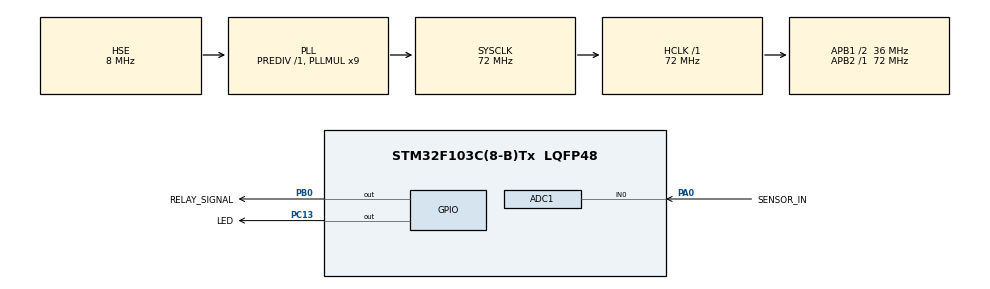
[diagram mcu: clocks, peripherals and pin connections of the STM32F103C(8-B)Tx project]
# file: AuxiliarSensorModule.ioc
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ADC1.Channel-3\#ChannelRegularConversion=ADC_CHANNEL_0
ADC1.ContinuousConvMode=DISABLE
ADC1.NbrOfConversionFlag=1
ADC1.Rank-3\#ChannelRegularConversion=1
ADC1.SamplingTime-3\#ChannelRegularConversion=ADC_SAMPLETIME_1CYCLE_5
ADC1.master=1
Dma.ADC1.0.Direction=DMA_PERIPH_TO_MEMORY
Dma.ADC1.0.Instance=DMA1_Channel1
Dma.ADC1.0.MemDataAlignment=DMA_MDATAALIGN_HALFWORD
Dma.ADC1.0.MemInc=DMA_MINC_ENABLE
Dma.ADC1.0.Mode=DMA_NORMAL
Dma.ADC1.0.PeriphDataAlignment=DMA_PDATAALIGN_HALFWORD
Dma.ADC1.0.PeriphInc=DMA_PINC_DISABLE
Dma.ADC1.0.Priority=DMA_PRIORITY_LOW
Dma.Request0=ADC1
Mcu.Family=STM32F1
Mcu.Name=STM32F103C(8-B)Tx
Mcu.Package=LQFP48
NVIC.ADC1_2_IRQn=true\:0\:0\:false\:false\:true\:true\:true\:true
NVIC.DMA1_Channel1_IRQn=true\:0\:0\:false\:false\:true\:false\:true\:true
NVIC.PriorityGroup=NVIC_PRIORITYGROUP_4
PA0-WKUP.GPIO_Label=SENSOR_IN
PA0-WKUP.Signal=ADCx_IN0
PA13.Mode=Serial_Wire
PA13.Signal=SYS_JTMS-SWDIO
PA14.Mode=Serial_Wire
PA14.Signal=SYS_JTCK-SWCLK
PB0.GPIO_Label=RELAY_SIGNAL
PB0.Signal=GPIO_Output
PC13-TAMPER-RTC.GPIO_Label=LED
PC13-TAMPER-RTC.Signal=GPIO_Output
PD0-OSC_IN.Mode=HSE-External-Oscillator
PD0-OSC_IN.Signal=RCC_OSC_IN
PD1-OSC_OUT.Mode=HSE-External-Oscillator
PD1-OSC_OUT.Signal=RCC_OSC_OUT
ProjectManager.HeapSize=0x200
ProjectManager.StackSize=0x400
ProjectManager.TargetToolchain=STM32CubeIDE
RCC.ADCPresc=RCC_ADCPCLK2_DIV6
RCC.AHBFreq_Value=72000000
RCC.APB1CLKDivider=RCC_HCLK_DIV2
RCC.APB1Freq_Value=36000000
RCC.APB1TimFreq_Value=72000000
RCC.APB2Freq_Value=72000000
RCC.APB2TimFreq_Value=72000000
RCC.HCLKFreq_Value=72000000
RCC.PLLMUL=RCC_PLL_MUL9
RCC.PLLSourceVirtual=RCC_PLLSOURCE_HSE
RCC.SYSCLKFreq_VALUE=72000000
RCC.SYSCLKSource=RCC_SYSCLKSOURCE_PLLCLK
RCC.USBFreq_Value=72000000
SH.ADCx_IN0.0=ADC1_IN0,IN0
board=custom

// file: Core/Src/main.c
/* USER CODE BEGIN Header */
/**
  ******************************************************************************
  * @file           : main.c
  * @brief          : Main program body
  ******************************************************************************
  * @attention
  *
  * Copyright (c) 2024 STMicroelectronics.
  * All rights reserved.
  *
  * This software is licensed under terms that can be found in the LICENSE file
  * in the root directory of this software component.
  * If no LICENSE file comes with this software, it is provided AS-IS.
  *
  ******************************************************************************
  */
/* USER CODE END Header */
#include "main.h"
#include "adc.h"
#include "dma.h"
#include "gpio.h"

/* USER CODE BEGIN Includes */
#include "stdio.h"
#include "stdbool.h"
#include "string.h"

/* USER CODE END Includes */

/* USER CODE BEGIN PD */
#define ANALOG_READS 1
#define VALUE_STAGE_1 1700 // 70 - 1.51V
#define VALUE_STAGE_2 500 // 110 - 0.64V
#define HISTERESYS 600 //
#define BUFFER_SIZE 10
/* USER CODE END PD */

/* USER CODE BEGIN PV */

/*  ADC  */
uint32_t ADCReadings[ANALOG_READS];
uint32_t anBuff[BUFFER_SIZE] = {0};
bool ADC_Complete = false;
uint32_t mediaRead = 0;
uint8_t buf_cnt = 0;

/*  TIMER  */
uint16_t timer_diff;
uint16_t timer_diff2;
uint16_t timer_diff3;

uint16_t timer_bfr = 0;
uint16_t timer_bfr2 = 0;
uint16_t timer_bfr3 = 0;

int point = 0;

uint16_t timer_curr = 0;
bool relay_status = true;

uint8_t read_cont = 0;

/* USER CODE END PV */

void SystemClock_Config(void);
/* USER CODE BEGIN PFP */

void HAL_ADC_ConvCpltCallback(ADC_HandleTypeDef* hadc);

/* USER CODE END PFP */

int main(void)
{

  /* MCU Configuration--------------------------------------------------------*/

  /* Reset of all peripherals, Initializes the Flash interface and the Systick. */
  HAL_Init();

  /* Configure the system clock */
  SystemClock_Config();

  /* Initialize all configured peripherals */
  MX_GPIO_Init();
  MX_DMA_Init();
  MX_ADC1_Init();
  /* USER CODE BEGIN 2 */

  /*
   * OBS: Uma breve inicialização com LED piscando para verificar que o controlador foi inicializado.
   * */
  for(int i = 0; i < 5; i++) {
	  HAL_GPIO_TogglePin(LED_GPIO_Port,LED_Pin);
	  HAL_Delay(200);
  }
  HAL_GPIO_WritePin(RELAY_SIGNAL_GPIO_Port, RELAY_SIGNAL_Pin, GPIO_PIN_SET);
  HAL_ADC_Start_DMA(&hadc1, (uint32_t*)&ADCReadings, ANALOG_READS);

  /* USER CODE END 2 */

  /* Infinite loop */
  /* USER CODE BEGIN WHILE */
  while (1)
  {
	  timer_curr = HAL_GetTick(); // OBS: Essa função retorna o valor em millissegundos.

	  HAL_GPIO_TogglePin(LED_GPIO_Port,LED_Pin);
	  // HAL_Delay(300); // OBS: Esse delay dentro do loop tá travando o seu código por 300ms a cada interação. Isso não se faz!

	  timer_diff = timer_curr - timer_bfr; // OBS: Show! Você inicializou tudo com 0 e como variáveis globais, então vai funcionar.

	  if (timer_diff >= 100) { // OBS: Você executa esse trecho de código a cada aproximadamento 100ms. OK!
		  HAL_ADC_Start_DMA(&hadc1, (uint32_t*)&ADCReadings, ANALOG_READS); // OBS: Habilita a amostragem do valor das analógicas utilizando DMA. OK!

		  if (ADC_Complete) {	// OBS: Aguarda até as analógicas serem completamente amostradas e convertidas pelo ADC. OK!
			  ADC_Complete = false; // OBS: Atualiza a variável de comunicação do loop com a interrupção. OK!
			  HAL_ADC_Stop_DMA(&hadc1);

			// OBS: Só posiciona o valor lido na analógica na posição da leitura mais antiga, e fica rodando essa variável 'buf_cnt'
			// OBS: Não interessa a posição do valor, no final das contas você vai somar tudo e dividir mesmo.
			anBuff[buf_cnt] = ADCReadings[0];
			buf_cnt++;
			if(buf_cnt == BUFFER_SIZE) {buf_cnt = 0;}

			// OBS: Adicionei a média aqui pois ela somente se altera quando se lê uma nova analógica, logo não faz sentido rodar ela em outro trecho do código
		    // Calcula a média dos valores em anBuff
		    uint32_t sum = 0;

		    for (int i = 0; i < BUFFER_SIZE; i++) {
		      sum += anBuff[i];
		    }
		    mediaRead = sum / BUFFER_SIZE;

      }
      // HAL_ADC_Start_DMA(&hadc1, (uint32_t*)&ADCReadings, ANALOG_READS); // OBS: Você já está habilitando a amostragem do valor das analógicas lá no inicio a cada 100ms.
      	  	  	  	  	  	  	  	  	  	  	  	  	  	  	  	  	   // OBS: Habilitando essa amostragem aqui você tá pedindo para o controlador inicializar a leitura e somente irá ler esse valor 100ms depois.
      	  	  	  	  	  	  	  	  	  	  	  	  	  	  	  	  	   // OBS: Quando você entrar no trecho que roda a cada 100ms o ADC_Complete já vai estar True e com o valor de 100ms atrás.
      timer_bfr = timer_curr; // OBS: Atualiza o novo valor de timer_bfr somente após completar o código completo que roda em 100ms (Amostragem e Leitura da analógica). OK!
    }

	timer_diff2 = timer_curr - timer_bfr2; // OBS: Pelo que entendi você vai usar outro conjunto de variáveis para controlar o tempo da outra função. Então vai precisar desse mesmo processo.
	timer_diff3 = timer_curr - timer_bfr3;
	// OBS: Daria para fazer usando a mesma variável, mas não importa muito para esse rpograma específico. Podemos fazer assim, sem problemas.

	if (timer_diff2 >= 10000) { // Esse trecho executa a cada 1 segundo. Coloquei 1 segundo e troquei a média movel para 10 valores. BUFFER_SIZE = 10;

		if (relay_status){
			// OBS: Observa como funciona a histerese. Depois que o relé liga quando a temperatura passa do VALUE_STAGE_1, ele só desliga depois que desce pelo menos a histerese dese alvo, senão não faz nada e permanece ligado.
			if (mediaRead > VALUE_STAGE_1 ){
				point = 1;
				relay_status = true; // OBS: Considerei o true como sendo a ventoinha ligada (relé desligado pois estamos usando NC do relé). VERIFICAR A LÓGICA!

			}
			if (mediaRead <= VALUE_STAGE_1 ){
				relay_status = false;
				point = 2;
			}

		} else {
			if(!relay_status){
				if(mediaRead >= VALUE_STAGE_1 + HISTERESYS){
					relay_status = true;
					point =3;
				}
			}

		}

		// OBS: Aqui atualiza o output do GPIO para acionamento do relé. OK! (Relé desligado é ventoinha ligada pois estamos usando o NC do relé. VERIFICAR A LÓGICA!
		if (relay_status){
			HAL_GPIO_WritePin(RELAY_SIGNAL_GPIO_Port, RELAY_SIGNAL_Pin, GPIO_PIN_SET);
		} else {
			HAL_GPIO_WritePin(RELAY_SIGNAL_GPIO_Port, RELAY_SIGNAL_Pin, GPIO_PIN_RESET);
		}

		timer_bfr2 = timer_curr;

	}

  }
  /* USER CODE END 3 */
}

void SystemClock_Config(void)
{
  RCC_OscInitTypeDef RCC_OscInitStruct = {0};
  RCC_ClkInitTypeDef RCC_ClkInitStruct = {0};
  RCC_PeriphCLKInitTypeDef PeriphClkInit = {0};

  /** Initializes the RCC Oscillators according to the specified parameters
  * in the RCC_OscInitTypeDef structure.
  */
  RCC_OscInitStruct.OscillatorType = RCC_OSCILLATORTYPE_HSE;
  RCC_OscInitStruct.HSEState = RCC_HSE_ON;
  RCC_OscInitStruct.HSEPredivValue = RCC_HSE_PREDIV_DIV1;
  RCC_OscInitStruct.HSIState = RCC_HSI_ON;
  RCC_OscInitStruct.PLL.PLLState = RCC_PLL_ON;
  RCC_OscInitStruct.PLL.PLLSource = RCC_PLLSOURCE_HSE;
  RCC_OscInitStruct.PLL.PLLMUL = RCC_PLL_MUL9;
  if (HAL_RCC_OscConfig(&RCC_OscInitStruct) != HAL_OK)
  {
    Error_Handler();
  }

  /** Initializes the CPU, AHB and APB buses clocks
  */
  RCC_ClkInitStruct.ClockType = RCC_CLOCKTYPE_HCLK|RCC_CLOCKTYPE_SYSCLK
                              |RCC_CLOCKTYPE_PCLK1|RCC_CLOCKTYPE_PCLK2;
  RCC_ClkInitStruct.SYSCLKSource = RCC_SYSCLKSOURCE_PLLCLK;
  RCC_ClkInitStruct.AHBCLKDivider = RCC_SYSCLK_DIV1;
  RCC_ClkInitStruct.APB1CLKDivider = RCC_HCLK_DIV2;
  RCC_ClkInitStruct.APB2CLKDivider = RCC_HCLK_DIV1;

  if (HAL_RCC_ClockConfig(&RCC_ClkInitStruct, FLASH_LATENCY_2) != HAL_OK)
  {
    Error_Handler();
  }
  PeriphClkInit.PeriphClockSelection = RCC_PERIPHCLK_ADC;
  PeriphClkInit.AdcClockSelection = RCC_ADCPCLK2_DIV6;
  if (HAL_RCCEx_PeriphCLKConfig(&PeriphClkInit) != HAL_OK)
  {
    Error_Handler();
  }
}

/* USER CODE BEGIN 4 */
void HAL_ADC_ConvCpltCallback(ADC_HandleTypeDef* hadc){
	if (hadc == &hadc1){

		ADC_Complete = true;

	}
}
/* USER CODE END 4 */

void Error_Handler(void)
{
  __disable_irq();
  while (1)
  {
  }
}
